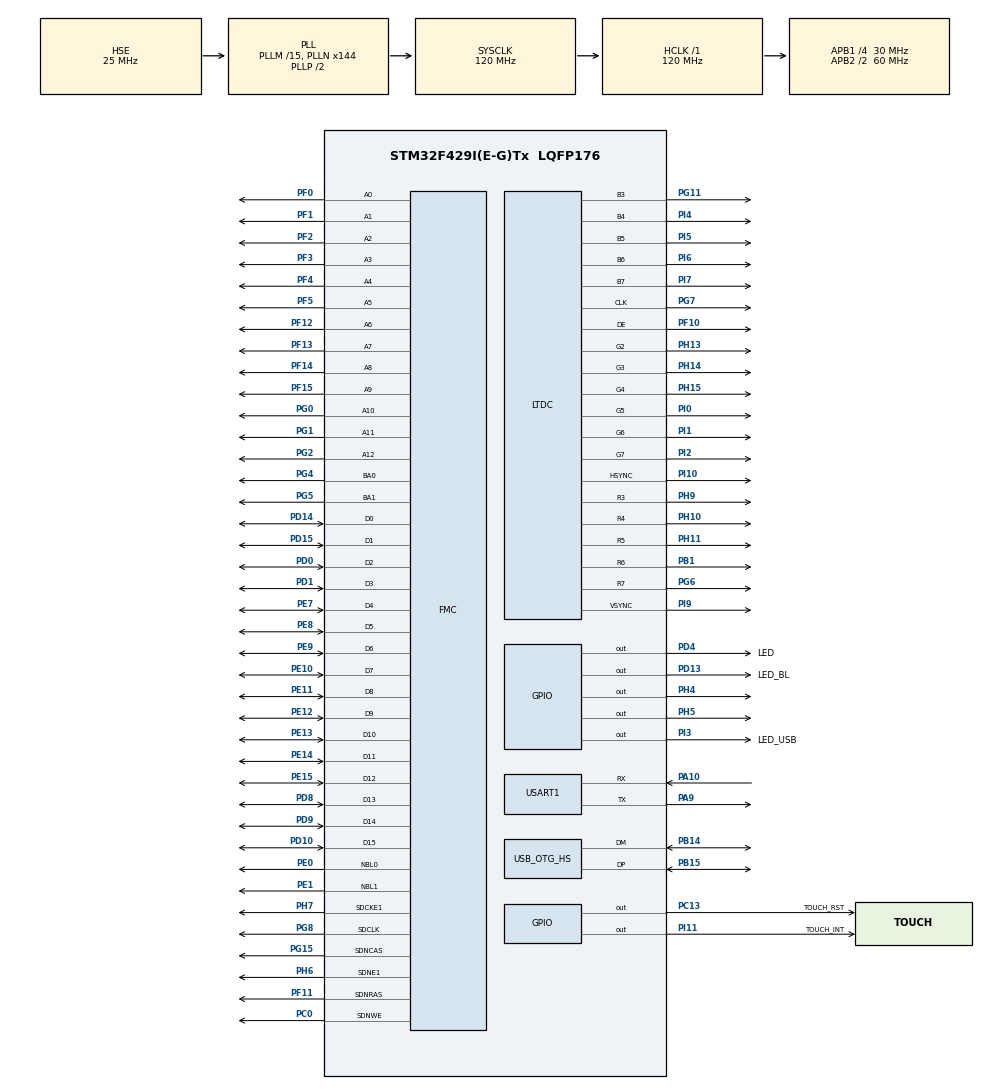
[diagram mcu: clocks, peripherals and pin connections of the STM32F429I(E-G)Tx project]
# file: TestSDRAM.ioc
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DMA2D.ColorMode=DMA2D_OUTPUT_RGB565
FATFS._CODE_PAGE=936
FATFS._USE_LFN=2
FMC.CASLatency1=FMC_SDRAM_CAS_LATENCY_3
FMC.ColumnBitsNumber1=FMC_SDRAM_COLUMN_BITS_NUM_9
FMC.ExitSelfRefreshDelay1=8
FMC.LoadToActiveDelay1=2
FMC.RCDDelay1=2
FMC.RPDelay1=2
FMC.RPDelay2=2
FMC.ReadPipeDelay1=FMC_SDRAM_RPIPE_DELAY_1
FMC.ReadPipeDelay2=FMC_SDRAM_RPIPE_DELAY_1
FMC.RowCycleDelay1=7
FMC.RowCycleDelay2=7
FMC.SDClockPeriod1=FMC_SDRAM_CLOCK_PERIOD_2
FMC.SDClockPeriod2=FMC_SDRAM_CLOCK_PERIOD_2
FMC.SelfRefreshTime1=6
FMC.WriteRecoveryTime1=5
LTDC.ActiveW=800
LTDC.Alpha_L0=255
LTDC.FBStartAdress_L0=0xD0000000
LTDC.HBP=88
LTDC.HFP=40
LTDC.HSync=88
LTDC.ImageHeight_L0=480
LTDC.ImageWidth_L0=800
LTDC.Layers=0
LTDC.PixelFormat_L0=LTDC_PIXEL_FORMAT_RGB565
LTDC.VBP=32
LTDC.VFP=13
LTDC.VSync=32
LTDC.WindowX1_L0=800
LTDC.WindowY1_L0=480
Mcu.Family=STM32F4
Mcu.Name=STM32F429I(E-G)Tx
Mcu.Package=LQFP176
NVIC.DMA2D_IRQn=true\:0\:0\:false\:false\:true\:true\:true
NVIC.FMC_IRQn=true\:0\:0\:false\:false\:true\:true\:true
NVIC.LTDC_IRQn=true\:0\:0\:false\:false\:true\:true\:true
NVIC.OTG_HS_IRQn=true\:0\:0\:false\:false\:true\:false\:true
NVIC.PriorityGroup=NVIC_PRIORITYGROUP_4
NVIC.TIM2_IRQn=true\:0\:0\:false\:false\:true\:true\:true
NVIC.USART1_IRQn=true\:0\:0\:false\:false\:true\:true\:true
PA10.Mode=Asynchronous
PA10.Signal=USART1_RX
PA13.Mode=Serial_Wire
PA13.Signal=SYS_JTMS-SWDIO
PA14.Mode=Serial_Wire
PA14.Signal=SYS_JTCK-SWCLK
PA9.Mode=Asynchronous
PA9.Signal=USART1_TX
PB1.GPIO_Speed=GPIO_SPEED_FREQ_VERY_HIGH
PB1.Mode=RGB565
PB1.Signal=LTDC_R6
PB14.Mode=Host_FS
PB14.Signal=USB_OTG_HS_DM
PB15.Mode=Host_FS
PB15.Signal=USB_OTG_HS_DP
PC0.Signal=FMC_SDNWE
PC13.GPIO_Label=TOUCH_RST
PC13.GPIO_PuPd=GPIO_PULLDOWN
PC13.Signal=GPIO_Output
PD0.Signal=FMC_D2_DA2
PD1.Signal=FMC_D3_DA3
PD10.Signal=FMC_D15_DA15
PD13.GPIO_Label=LED_BL
PD13.GPIO_PuPd=GPIO_PULLUP
PD13.Signal=GPIO_Output
PD14.Signal=FMC_D0_DA0
PD15.Signal=FMC_D1_DA1
PD4.GPIO_Label=LED
PD4.GPIO_PuPd=GPIO_PULLUP
PD4.PinState=GPIO_PIN_RESET
PD4.Signal=GPIO_Output
PD8.Signal=FMC_D13_DA13
PD9.Signal=FMC_D14_DA14
PE0.Signal=FMC_NBL0
PE1.Signal=FMC_NBL1
PE10.Signal=FMC_D7_DA7
PE11.Signal=FMC_D8_DA8
PE12.Signal=FMC_D9_DA9
PE13.Signal=FMC_D10_DA10
PE14.Signal=FMC_D11_DA11
PE15.Signal=FMC_D12_DA12
PE7.Signal=FMC_D4_DA4
PE8.Signal=FMC_D5_DA5
PE9.Signal=FMC_D6_DA6
PF0.Signal=FMC_A0
PF1.Signal=FMC_A1
PF10.GPIO_Speed=GPIO_SPEED_FREQ_VERY_HIGH
PF10.Mode=RGB565
PF10.Signal=LTDC_DE
PF11.Signal=FMC_SDNRAS
PF12.Signal=FMC_A6
PF13.Signal=FMC_A7
PF14.Signal=FMC_A8
PF15.Signal=FMC_A9
PF2.Signal=FMC_A2
PF3.Signal=FMC_A3
PF4.Signal=FMC_A4
PF5.Signal=FMC_A5
PG0.Signal=FMC_A10
PG1.Signal=FMC_A11
PG11.GPIO_Speed=GPIO_SPEED_FREQ_VERY_HIGH
PG11.Mode=RGB565
PG11.Signal=LTDC_B3
PG15.Signal=FMC_SDNCAS
PG2.Signal=FMC_A12
PG4.Signal=FMC_A14_BA0
PG5.Signal=FMC_A15_BA1
PG6.GPIO_Speed=GPIO_SPEED_FREQ_VERY_HIGH
PG6.Mode=RGB565
PG6.Signal=LTDC_R7
PG7.GPIO_Speed=GPIO_SPEED_FREQ_VERY_HIGH
PG7.Mode=RGB565
PG7.Signal=LTDC_CLK
PG8.Signal=FMC_SDCLK
PH0/OSC_IN.Mode=HSE-External-Oscillator
PH0/OSC_IN.Signal=RCC_OSC_IN
PH1/OSC_OUT.Mode=HSE-External-Oscillator
PH1/OSC_OUT.Signal=RCC_OSC_OUT
PH10.GPIO_Speed=GPIO_SPEED_FREQ_VERY_HIGH
PH10.Mode=RGB565
PH10.Signal=LTDC_R4
PH11.GPIO_Speed=GPIO_SPEED_FREQ_VERY_HIGH
PH11.Mode=RGB565
PH11.Signal=LTDC_R5
PH13.GPIO_Speed=GPIO_SPEED_FREQ_VERY_HIGH
PH13.Mode=RGB565
PH13.Signal=LTDC_G2
PH14.GPIO_Speed=GPIO_SPEED_FREQ_VERY_HIGH
PH14.Mode=RGB565
PH14.Signal=LTDC_G3
PH15.GPIO_Speed=GPIO_SPEED_FREQ_VERY_HIGH
PH15.Mode=RGB565
PH15.Signal=LTDC_G4
PH4.GPIO_PuPd=GPIO_PULLUP
PH4.GPIO_Speed=GPIO_SPEED_FREQ_MEDIUM
PH4.Signal=GPIO_Output
PH5.GPIO_ModeDefaultOutputPP=GPIO_MODE_OUTPUT_OD
PH5.GPIO_Speed=GPIO_SPEED_FREQ_MEDIUM
PH5.Signal=GPIO_Output
PH6.Mode=SdramChipSelect2_1
PH6.Signal=FMC_SDNE1
PH7.Mode=SdramChipSelect2_1
PH7.Signal=FMC_SDCKE1
PH9.GPIO_Speed=GPIO_SPEED_FREQ_VERY_HIGH
PH9.Mode=RGB565
PH9.Signal=LTDC_R3
PI0.GPIO_Speed=GPIO_SPEED_FREQ_VERY_HIGH
PI0.Mode=RGB565
PI0.Signal=LTDC_G5
PI1.GPIO_Speed=GPIO_SPEED_FREQ_VERY_HIGH
PI1.Mode=RGB565
PI1.Signal=LTDC_G6
PI10.GPIO_Speed=GPIO_SPEED_FREQ_VERY_HIGH
PI10.Mode=RGB565
PI10.Signal=LTDC_HSYNC
PI11.GPIO_Label=TOUCH_INT
PI11.GPIO_PuPd=GPIO_PULLUP
PI11.Signal=GPIO_Output
PI2.GPIO_Speed=GPIO_SPEED_FREQ_VERY_HIGH
PI2.Mode=RGB565
PI2.Signal=LTDC_G7
PI3.GPIO_Label=LED_USB
PI3.GPIO_PuPd=GPIO_PULLUP
PI3.GPIO_Speed=GPIO_SPEED_FREQ_MEDIUM
PI3.PinState=GPIO_PIN_SET
PI3.Signal=GPIO_Output
PI4.GPIO_Speed=GPIO_SPEED_FREQ_VERY_HIGH
PI4.Mode=RGB565
PI4.Signal=LTDC_B4
PI5.GPIO_Speed=GPIO_SPEED_FREQ_VERY_HIGH
PI5.Mode=RGB565
PI5.Signal=LTDC_B5
PI6.GPIO_Speed=GPIO_SPEED_FREQ_VERY_HIGH
PI6.Mode=RGB565
PI6.Signal=LTDC_B6
PI7.GPIO_Speed=GPIO_SPEED_FREQ_VERY_HIGH
PI7.Mode=RGB565
PI7.Signal=LTDC_B7
PI9.GPIO_Speed=GPIO_SPEED_FREQ_VERY_HIGH
PI9.Mode=RGB565
PI9.Signal=LTDC_VSYNC
ProjectManager.HeapSize=0x200
ProjectManager.StackSize=0x400
ProjectManager.TargetToolchain=STM32CubeIDE
RCC.48MHZClocksFreq_Value=48000000
RCC.AHBFreq_Value=120000000
RCC.APB1CLKDivider=RCC_HCLK_DIV4
RCC.APB1Freq_Value=30000000
RCC.APB1TimFreq_Value=60000000
RCC.APB2CLKDivider=RCC_HCLK_DIV2
RCC.APB2Freq_Value=60000000
RCC.APB2TimFreq_Value=120000000
RCC.CortexFreq_Value=120000000
RCC.HCLKFreq_Value=120000000
RCC.HSE_VALUE=25000000
RCC.HSI_VALUE=16000000
RCC.LSE_VALUE=32768
RCC.PLLM=15
RCC.PLLN=144
RCC.PLLQ=5
RCC.PLLSAIN=60
RCC.SYSCLKFreq_VALUE=120000000
RCC.SYSCLKSource=RCC_SYSCLKSOURCE_PLLCLK
RCC.VCOOutputFreq_Value=240000000
SH.FMC_A0.0=FMC_A0,13b-sda1
SH.FMC_A1.0=FMC_A1,13b-sda1
SH.FMC_A10.0=FMC_A10,13b-sda1
SH.FMC_A11.0=FMC_A11,13b-sda1
SH.FMC_A12.0=FMC_A12,13b-sda1
SH.FMC_A14_BA0.0=FMC_BA0,FourSdramBanks1
SH.FMC_A15_BA1.0=FMC_BA1,FourSdramBanks1
SH.FMC_A2.0=FMC_A2,13b-sda1
SH.FMC_A3.0=FMC_A3,13b-sda1
SH.FMC_A4.0=FMC_A4,13b-sda1
SH.FMC_A5.0=FMC_A5,13b-sda1
SH.FMC_A6.0=FMC_A6,13b-sda1
SH.FMC_A7.0=FMC_A7,13b-sda1
SH.FMC_A8.0=FMC_A8,13b-sda1
SH.FMC_A9.0=FMC_A9,13b-sda1
SH.FMC_D0_DA0.0=FMC_D0,sd-16b-d1
SH.FMC_D10_DA10.0=FMC_D10,sd-16b-d1
SH.FMC_D11_DA11.0=FMC_D11,sd-16b-d1
SH.FMC_D12_DA12.0=FMC_D12,sd-16b-d1
SH.FMC_D13_DA13.0=FMC_D13,sd-16b-d1
SH.FMC_D14_DA14.0=FMC_D14,sd-16b-d1
SH.FMC_D15_DA15.0=FMC_D15,sd-16b-d1
SH.FMC_D1_DA1.0=FMC_D1,sd-16b-d1
SH.FMC_D2_DA2.0=FMC_D2,sd-16b-d1
SH.FMC_D3_DA3.0=FMC_D3,sd-16b-d1
SH.FMC_D4_DA4.0=FMC_D4,sd-16b-d1
SH.FMC_D5_DA5.0=FMC_D5,sd-16b-d1
SH.FMC_D6_DA6.0=FMC_D6,sd-16b-d1
SH.FMC_D7_DA7.0=FMC_D7,sd-16b-d1
SH.FMC_D8_DA8.0=FMC_D8,sd-16b-d1
SH.FMC_D9_DA9.0=FMC_D9,sd-16b-d1
SH.FMC_NBL0.0=FMC_NBL0,Sd2ByteEnable1
SH.FMC_NBL1.0=FMC_NBL1,Sd2ByteEnable1
SH.FMC_SDCLK.0=FMC_SDCLK,13b-sda1
SH.FMC_SDNCAS.0=FMC_SDNCAS,13b-sda1
SH.FMC_SDNRAS.0=FMC_SDNRAS,13b-sda1
SH.FMC_SDNWE.0=FMC_SDNWE,13b-sda1
STMicroelectronics.X-CUBE-TOUCHGFX.4.15.0.ApplicationCcGraphicsJjApplication=TouchGFXOoGenerator
STMicroelectronics.X-CUBE-TOUCHGFX.4.15.0.tgfx_address1=0xD0000000
STMicroelectronics.X-CUBE-TOUCHGFX.4.15.0.tgfx_display_interface=disp_ltdc
STMicroelectronics.X-CUBE-TOUCHGFX.4.15.0.tgfx_hardware_accelerator=dma_2d
STMicroelectronics.X-CUBE-TOUCHGFX.4.15.0.tgfx_location=By Address
STMicroelectronics.X-CUBE-TOUCHGFX.4.15.0.tgfx_vsync=vsync_ltdc
TIM2.Period=1000 - 1
TIM2.Prescaler=90 - 1
USART1.VirtualMode=VM_ASYNC
USB_HOST.BSP.number=1
USB_HOST.USBH_HandleTypeDef-MSC_HS=hUsbHostHS
USB_HOST.VirtualModeHS=Msc
USB_HOST0.BSP.STBoard=false
USB_HOST0.BSP.api=Unknown
USB_HOST0.BSP.i2caddr=0
USB_HOST0.BSP.instance=PI3
USB_HOST0.BSP.ip=GPIO
USB_HOST0.BSP.mode=Output
USB_HOST0.BSP.name=Drive_VBUS_HS
USB_HOST0.BSP.solution=PI3
USB_OTG_HS.VirtualMode-Host_FS=Host_FS
VP_CRC_VS_CRC.Mode=CRC_Activate
VP_DMA2D_VS_DMA2D.Mode=DMA2D_Activate
VP_FATFS_VS_USB.Mode=USB
VP_STMicroelectronics.X-CUBE-TOUCHGFX_VS_GraphicsJjApplication_4.15.0.Mode=GraphicsJjApplication
VP_TIM2_VS_ClockSourceINT.Mode=Internal
VP_USB_HOST_VS_USB_HOST_MSC_HS.Mode=MSC_HS
board=custom

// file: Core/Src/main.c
/* USER CODE BEGIN Header */
/**
  ******************************************************************************
  * @file           : main.c
  * @brief          : Main program body
  ******************************************************************************
  * @attention
  *
  * <h2><center>&copy; Copyright (c) 2020 STMicroelectronics.
  * All rights reserved.</center></h2>
  *
  * This software component is licensed by ST under BSD 3-Clause license,
  * the "License"; You may not use this file except in compliance with the
  * License. You may obtain a copy of the License at:
  *                        opensource.org/licenses/BSD-3-Clause
  *
  ******************************************************************************
  */
/* USER CODE END Header */
#include "main.h"
#include "crc.h"
#include "dma2d.h"
#include "fatfs.h"
#include "ltdc.h"
#include "tim.h"
#include "usart.h"
#include "usb_host.h"
#include "gpio.h"
#include "fmc.h"
#include "app_touchgfx.h"

/* USER CODE BEGIN Includes */
#include <stdio.h>
#include "sdram_fmc_drv.h"
#include "touch_800x480.h"
#include "usbh_core.h"
#include "USBDisk.h"

/* USER CODE END Includes */

/* USER CODE BEGIN PTD */
#ifdef __GNUC__
#define PUTCHAR_PROTOTYPE int __io_putchar(int ch)
#else
#define PUTCHAR_PROTOTYPE int fputc(int ch, FILE *f)
#endif

PUTCHAR_PROTOTYPE {
    while ((USART1->SR & 0X40) == 0);
    USART1->DR = (uint8_t) ch;
    return ch;
}
/* USER CODE END PTD */

void SystemClock_Config(void);
void MX_USB_HOST_Process(void);

/* USER CODE BEGIN 0 */

#define EXT_SDRAM_ADDR		((uint32_t)0xD0000000)
#define EXT_SDRAM_SIZE		(32 * 1024 * 1024)

uint32_t bsp_TestExtSDRAM(void);

uint8_t timer_irq = 0;
uint8_t touch_cnt = 0;

uint8_t pre_state;

void timer_loop(void) {
	if(timer_irq == 0) return;
	timer_irq = 0;

	touch_cnt++;
	if(touch_cnt > 20) {
		touch_cnt = 0;
		Touch_Scan();
	}

	MX_USB_HOST_Process();

	if (pre_state != Appli_state) {
		switch(Appli_state) {
			case APPLICATION_DISCONNECT: //USB flash disk remove
				/* Register the file system object to the FatFs module */
				printf("APPLICATION_DISCONNECT. \r\n");
				if(f_mount(NULL, "", 0) != FR_OK) {
					USBH_UsrLog("ERROR : Cannot exit FatFs! \n");
				}
				break;
			case APPLICATION_READY:   //USB flash disk plugin
				/* Open or create a log file and ready to append */
				printf("APPLICATION_READY. \r\n");
				if(f_mount(&USBDISKFatFs, (TCHAR const*)USBHPath, 0) != FR_OK) {
					printf("f_mount fails. \r\n");
					break;
				} else {
					printf("f_mount success. \r\n");
					Explore_Disk(USBHPath, 1);
				}

				break;
			default:
				break;
		}
	}
	pre_state = Appli_state;

//	switch(Appli_state) {
//		case APPLICATION_READY:
////			if(rUSB == 0) {
////	            printf("APPLICATION_READY.\r\n");
//				// MSC_Application();
//				Explore_Disk("0:/", 1);
////			}
//			// Appli_state = APPLICATION_DISCONNECT;
//			rUSB = 1;
//			break;
//		case APPLICATION_DISCONNECT:
//			f_mount(NULL, "", 0);
//			break;
//		default:
//			break;
//	}
}

/* USER CODE END 0 */

int main(void)
{
  /* USER CODE BEGIN 1 */
  Appli_state = APPLICATION_IDLE;
  pre_state = Appli_state;
  /* USER CODE END 1 */

  /* MCU Configuration--------------------------------------------------------*/

  /* Reset of all peripherals, Initializes the Flash interface and the Systick. */
  HAL_Init();

  /* Configure the system clock */
  SystemClock_Config();

  /* Initialize all configured peripherals */
  MX_GPIO_Init();
  MX_FMC_Init();
  MX_TIM2_Init();
  MX_LTDC_Init();
  MX_DMA2D_Init();
  MX_CRC_Init();
  MX_USART1_UART_Init();
  MX_USB_HOST_Init();
  MX_FATFS_Init();
  MX_TouchGFX_Init();
  /* USER CODE BEGIN 2 */

  // 点亮 LED
  HAL_GPIO_WritePin(LED_GPIO_Port, LED_Pin, GPIO_PIN_RESET);

  HAL_TIM_Base_Start_IT(&htim2);

  SDRAM_Init();

  HAL_Delay(100);

  // 点亮 LCD
  HAL_GPIO_WritePin(LED_BL_GPIO_Port, LED_BL_Pin, GPIO_PIN_SET);

  printf("System running... \r\n");

  Touch_Init();				// 触摸屏初始化

//  uint32_t i;
//  uint32_t *pSRAM;
//
//  /* 写SDRAM */
//  pSRAM = (uint32_t *)EXT_SDRAM_ADDR;
//  for (i = 0; i < 800 * 50; i++)
//  {
//      *pSRAM++ = 0x33;
//  }

//  if (bsp_TestExtSDRAM() == 0) {
//    HAL_GPIO_WritePin(LED_GPIO_Port, LED_Pin, GPIO_PIN_SET);
//  } else {
//    HAL_GPIO_WritePin(LED_GPIO_Port, LED_Pin, GPIO_PIN_RESET);
//  }

  /* USER CODE END 2 */

  /* Infinite loop */
  while (1)
  {
    // MX_USB_HOST_Process();
	timer_loop();
    MX_TouchGFX_Process();
  }
}

void SystemClock_Config(void)
{
  RCC_OscInitTypeDef RCC_OscInitStruct = {0};
  RCC_ClkInitTypeDef RCC_ClkInitStruct = {0};
  RCC_PeriphCLKInitTypeDef PeriphClkInitStruct = {0};

  /** Configure the main internal regulator output voltage
  */
  __HAL_RCC_PWR_CLK_ENABLE();
  __HAL_PWR_VOLTAGESCALING_CONFIG(PWR_REGULATOR_VOLTAGE_SCALE3);
  /** Initializes the RCC Oscillators according to the specified parameters
  * in the RCC_OscInitTypeDef structure.
  */
  RCC_OscInitStruct.OscillatorType = RCC_OSCILLATORTYPE_HSE;
  RCC_OscInitStruct.HSEState = RCC_HSE_ON;
  RCC_OscInitStruct.PLL.PLLState = RCC_PLL_ON;
  RCC_OscInitStruct.PLL.PLLSource = RCC_PLLSOURCE_HSE;
  RCC_OscInitStruct.PLL.PLLM = 15;
  RCC_OscInitStruct.PLL.PLLN = 144;
  RCC_OscInitStruct.PLL.PLLP = RCC_PLLP_DIV2;
  RCC_OscInitStruct.PLL.PLLQ = 5;
  if (HAL_RCC_OscConfig(&RCC_OscInitStruct) != HAL_OK)
  {
    Error_Handler();
  }
  /** Initializes the CPU, AHB and APB buses clocks
  */
  RCC_ClkInitStruct.ClockType = RCC_CLOCKTYPE_HCLK|RCC_CLOCKTYPE_SYSCLK
                              |RCC_CLOCKTYPE_PCLK1|RCC_CLOCKTYPE_PCLK2;
  RCC_ClkInitStruct.SYSCLKSource = RCC_SYSCLKSOURCE_PLLCLK;
  RCC_ClkInitStruct.AHBCLKDivider = RCC_SYSCLK_DIV1;
  RCC_ClkInitStruct.APB1CLKDivider = RCC_HCLK_DIV4;
  RCC_ClkInitStruct.APB2CLKDivider = RCC_HCLK_DIV2;

  if (HAL_RCC_ClockConfig(&RCC_ClkInitStruct, FLASH_LATENCY_3) != HAL_OK)
  {
    Error_Handler();
  }
  PeriphClkInitStruct.PeriphClockSelection = RCC_PERIPHCLK_LTDC;
  PeriphClkInitStruct.PLLSAI.PLLSAIN = 60;
  PeriphClkInitStruct.PLLSAI.PLLSAIR = 2;
  PeriphClkInitStruct.PLLSAIDivR = RCC_PLLSAIDIVR_2;
  if (HAL_RCCEx_PeriphCLKConfig(&PeriphClkInitStruct) != HAL_OK)
  {
    Error_Handler();
  }
}

/* USER CODE BEGIN 4 */

void HAL_GPIO_EXTI_Callback(uint16_t GPIO_Pin)
{

  if(GPIO_Pin == TOUCH_INT_Pin)
  {
    // HAL_GPIO_TogglePin(LED_GPIO_Port, LED_Pin);
    // 清除标志
    __HAL_GPIO_EXTI_CLEAR_IT(GPIO_Pin);
  }
}

uint32_t bsp_TestExtSDRAM(void)
{
    uint32_t i;
    uint32_t *pSRAM;
    uint8_t *pBytes;
    uint32_t err;
    const uint8_t ByteBuf[4] = {0x55, 0xA5, 0x5A, 0xAA};

    /* 写SDRAM */
    pSRAM = (uint32_t *)EXT_SDRAM_ADDR;
    for (i = 0; i < EXT_SDRAM_SIZE / 4; i++)
    {
        *pSRAM++ = i;
    }

    /* 读SDRAM */
    err = 0;
    pSRAM = (uint32_t *)EXT_SDRAM_ADDR;
    for (i = 0; i < EXT_SDRAM_SIZE / 4; i++)
    {
        if (*pSRAM++ != i)
        {
            err++;
        }
    }

    if (err >  0)
    {
        return  (4 * err);
    }

    /* 对SDRAM 的数据求反并写入 */
    pSRAM = (uint32_t *)EXT_SDRAM_ADDR;
    for (i = 0; i < EXT_SDRAM_SIZE / 4; i++)
    {
        *pSRAM = ~*pSRAM;
        pSRAM++;
    }

    /* 再次比较SDRAM的数�????????????? */
    err = 0;
    pSRAM = (uint32_t *)EXT_SDRAM_ADDR;
    for (i = 0; i < EXT_SDRAM_SIZE / 4; i++)
    {
        if (*pSRAM++ != (~i))
        {
            err++;
        }
    }

    if (err >  0)
    {
        return (4 * err);
    }

    /* 测试按字节方式访�?????????????, 目的是验�????????????? FSMC_NBL0 �????????????? FSMC_NBL1 口线 */
    pBytes = (uint8_t *)EXT_SDRAM_ADDR;
    for (i = 0; i < sizeof(ByteBuf); i++)
    {
        *pBytes++ = ByteBuf[i];
    }

    /* 比较SDRAM的数�????????????? */
    err = 0;
    pBytes = (uint8_t *)EXT_SDRAM_ADDR;
    for (i = 0; i < sizeof(ByteBuf); i++)
    {
        if (*pBytes++ != ByteBuf[i])
        {
            err++;
        }
    }
    if (err >  0)
    {
        return err;
    }
    return 0;
}

/* USER CODE END 4 */

void Error_Handler(void)
{
}

/************************ (C) COPYRIGHT STMicroelectronics *****END OF FILE****/
